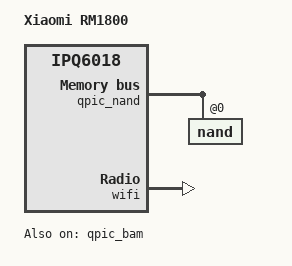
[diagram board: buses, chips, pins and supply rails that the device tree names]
// SPDX-License-Identifier: GPL-2.0-or-later OR MIT

/dts-v1/;

#include "ipq6000-xiaomi.dtsi"

/ {
	model = "Xiaomi RM1800";
	compatible = "xiaomi,rm1800", "qcom,ipq6018";

	chosen {
		stdout-path = "serial0:115200n8";
		bootargs-append = " root=/dev/ubiblock0_1";
	};
};

&qpic_bam {
	status = "okay";
};

&qpic_nand {
	status = "okay";

	nand@0 {
		reg = <0>;
		nand-ecc-strength = <4>;
		nand-ecc-step-size = <512>;
		nand-bus-width = <8>;

		partitions {
			compatible = "qcom,smem-part";
		};
	};
};

&wifi {
	qcom,ath11k-fw-memory-mode = <2>;
};
